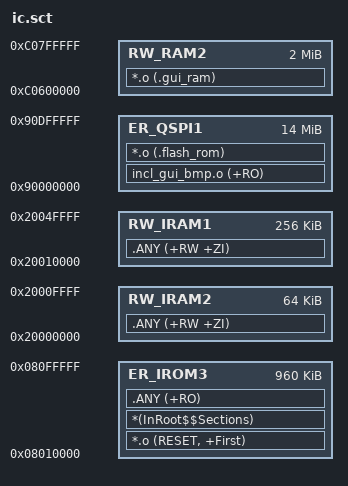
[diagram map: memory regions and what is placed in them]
; *************************************************************
; *** Scatter-Loading Description File generated by uVision ***
; *************************************************************
                  
LR_IROM3 0x08010000 0xF0000    		; load region size_region  
{
	ER_IROM3 0x08010000 0xF0000  	; load address = execution address  
	{
		*.o (RESET, +First)
		*(InRoot$$Sections)
		.ANY (+RO)
	}
    RW_IRAM1 0x20010000 0x00040000  
    {
        .ANY (+RW +ZI)
    }
    RW_IRAM2 0x20000000 0x00010000  
    {
        .ANY (+RW +ZI)
    }
	RW_RAM2	0xC0600000 0x00200000  	; SDRAM (2MB)
	{  
		*.o (.gui_ram)              ; GUI ram
	}
}


LR_QSPI1 0x90000000 0xE00000 
{	  

    ER_QSPI1 0x90000000 0xE00000
	{
		incl_gui_bmp.o (+RO)
        *.o (.flash_rom)
	}  
}
